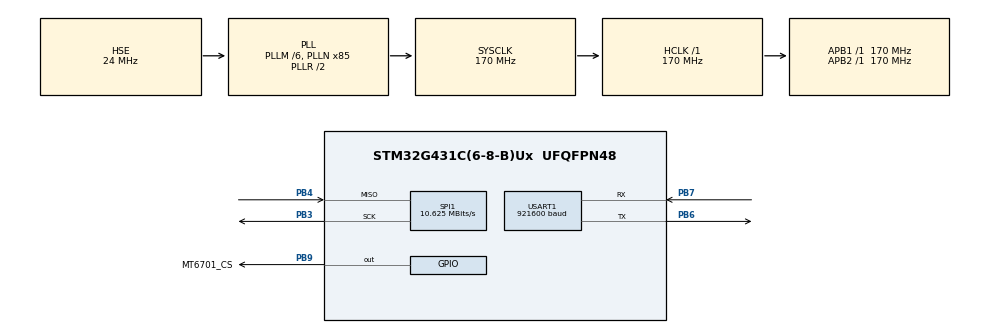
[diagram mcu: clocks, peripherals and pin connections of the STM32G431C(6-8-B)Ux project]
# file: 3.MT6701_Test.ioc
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Dma.Request0=USART1_TX
Dma.USART1_TX.0.Direction=DMA_MEMORY_TO_PERIPH
Dma.USART1_TX.0.EventEnable=DISABLE
Dma.USART1_TX.0.Instance=DMA1_Channel1
Dma.USART1_TX.0.MemDataAlignment=DMA_MDATAALIGN_BYTE
Dma.USART1_TX.0.MemInc=DMA_MINC_ENABLE
Dma.USART1_TX.0.Mode=DMA_NORMAL
Dma.USART1_TX.0.PeriphDataAlignment=DMA_PDATAALIGN_BYTE
Dma.USART1_TX.0.PeriphInc=DMA_PINC_DISABLE
Dma.USART1_TX.0.Polarity=HAL_DMAMUX_REQ_GEN_RISING
Dma.USART1_TX.0.Priority=DMA_PRIORITY_LOW
Dma.USART1_TX.0.RequestNumber=1
Dma.USART1_TX.0.SignalID=NONE
Dma.USART1_TX.0.SyncEnable=DISABLE
Dma.USART1_TX.0.SyncPolarity=HAL_DMAMUX_SYNC_NO_EVENT
Dma.USART1_TX.0.SyncRequestNumber=1
Dma.USART1_TX.0.SyncSignalID=NONE
Mcu.Family=STM32G4
Mcu.Name=STM32G431C(6-8-B)Ux
Mcu.Package=UFQFPN48
NVIC.DMA1_Channel1_IRQn=true\:0\:0\:false\:false\:true\:false\:true\:true
NVIC.PriorityGroup=NVIC_PRIORITYGROUP_4
NVIC.USART1_IRQn=true\:0\:0\:false\:false\:true\:true\:true\:true
PA13.Mode=Serial_Wire
PA13.Signal=SYS_JTMS-SWDIO
PA14.Mode=Serial_Wire
PA14.Signal=SYS_JTCK-SWCLK
PB3.Mode=RX_Only_Simplex_Unidirect_Master
PB3.Signal=SPI1_SCK
PB4.Mode=RX_Only_Simplex_Unidirect_Master
PB4.Signal=SPI1_MISO
PB6.Mode=Asynchronous
PB6.Signal=USART1_TX
PB7.Mode=Asynchronous
PB7.Signal=USART1_RX
PB9.GPIO_Label=MT6701_CS
PB9.GPIO_Speed=GPIO_SPEED_FREQ_MEDIUM
PB9.PinState=GPIO_PIN_SET
PB9.Signal=GPIO_Output
PF0-OSC_IN.Mode=HSE-External-Oscillator
PF0-OSC_IN.Signal=RCC_OSC_IN
PF1-OSC_OUT.Mode=HSE-External-Oscillator
PF1-OSC_OUT.Signal=RCC_OSC_OUT
ProjectManager.HeapSize=0x200
ProjectManager.StackSize=0x400
ProjectManager.TargetToolchain=MDK-ARM V5.32
RCC.ADC12Freq_Value=170000000
RCC.AHBFreq_Value=170000000
RCC.APB1Freq_Value=170000000
RCC.APB1TimFreq_Value=170000000
RCC.APB2Freq_Value=170000000
RCC.APB2TimFreq_Value=170000000
RCC.CortexFreq_Value=170000000
RCC.EXTERNAL_CLOCK_VALUE=12288000
RCC.HCLKFreq_Value=170000000
RCC.HSE_VALUE=24000000
RCC.HSI48_VALUE=48000000
RCC.HSI_VALUE=16000000
RCC.LSE_VALUE=32768
RCC.PLLM=RCC_PLLM_DIV6
RCC.PLLN=85
RCC.PLLSourceVirtual=RCC_PLLSOURCE_HSE
RCC.SYSCLKFreq_VALUE=170000000
RCC.SYSCLKSource=RCC_SYSCLKSOURCE_PLLCLK
RCC.USBFreq_Value=170000000
RCC.VCOOutputFreq_Value=340000000
SPI1.BaudRatePrescaler=SPI_BAUDRATEPRESCALER_16
SPI1.CLKPhase=SPI_PHASE_2EDGE
SPI1.CLKPolarity=SPI_POLARITY_LOW
SPI1.CalculateBaudRate=10.625 MBits/s
SPI1.DataSize=SPI_DATASIZE_16BIT
SPI1.Direction=SPI_DIRECTION_2LINES_RXONLY
SPI1.Mode=SPI_MODE_MASTER
SPI1.VirtualType=VM_MASTER
USART1.BaudRate=921600
USART1.VirtualMode-Asynchronous=VM_ASYNC
VP_SYS_VS_DBSignals.Mode=DisableDeadBatterySignals
board=custom

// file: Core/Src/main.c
/* USER CODE BEGIN Header */
/**
 ******************************************************************************
 * @file           : main.c
 * @brief          : Main program body
 ******************************************************************************
 * @attention
 *
 * Copyright (c) 2024 STMicroelectronics.
 * All rights reserved.
 *
 * This software is licensed under terms that can be found in the LICENSE file
 * in the root directory of this software component.
 * If no LICENSE file comes with this software, it is provided AS-IS.
 *
 ******************************************************************************
 */
/* USER CODE END Header */
#include "main.h"
#include "dma.h"
#include "spi.h"
#include "usart.h"
#include "gpio.h"

/* USER CODE BEGIN Includes */
#include "Serial.h"
#include "MT6701.h"
/* USER CODE END Includes */

void SystemClock_Config(void);

int main(void)
{

  /* MCU Configuration--------------------------------------------------------*/

  /* Reset of all peripherals, Initializes the Flash interface and the Systick. */
  HAL_Init();

  /* Configure the system clock */
  SystemClock_Config();

  /* Initialize all configured peripherals */
  MX_GPIO_Init();
  MX_DMA_Init();
  MX_USART1_UART_Init();
  MX_SPI1_Init();
  /* USER CODE BEGIN 2 */
  log_DMA_TX("MT6701 TEST\r\n");
  /* USER CODE END 2 */

  /* Infinite loop */
  /* USER CODE BEGIN WHILE */
  while (1)
  {
    float angle = MT6701_GetRawAngle();
    log_DMA_TX("angle:%f\r\n", angle);
    /* USER CODE END WHILE */

  }
}

void SystemClock_Config(void)
{
  RCC_OscInitTypeDef RCC_OscInitStruct = {0};
  RCC_ClkInitTypeDef RCC_ClkInitStruct = {0};

  /** Configure the main internal regulator output voltage
   */
  HAL_PWREx_ControlVoltageScaling(PWR_REGULATOR_VOLTAGE_SCALE1_BOOST);

  /** Initializes the RCC Oscillators according to the specified parameters
   * in the RCC_OscInitTypeDef structure.
   */
  RCC_OscInitStruct.OscillatorType = RCC_OSCILLATORTYPE_HSE;
  RCC_OscInitStruct.HSEState = RCC_HSE_ON;
  RCC_OscInitStruct.PLL.PLLState = RCC_PLL_ON;
  RCC_OscInitStruct.PLL.PLLSource = RCC_PLLSOURCE_HSE;
  RCC_OscInitStruct.PLL.PLLM = RCC_PLLM_DIV6;
  RCC_OscInitStruct.PLL.PLLN = 85;
  RCC_OscInitStruct.PLL.PLLP = RCC_PLLP_DIV2;
  RCC_OscInitStruct.PLL.PLLQ = RCC_PLLQ_DIV2;
  RCC_OscInitStruct.PLL.PLLR = RCC_PLLR_DIV2;
  if (HAL_RCC_OscConfig(&RCC_OscInitStruct) != HAL_OK)
  {
    Error_Handler();
  }

  /** Initializes the CPU, AHB and APB buses clocks
   */
  RCC_ClkInitStruct.ClockType = RCC_CLOCKTYPE_HCLK | RCC_CLOCKTYPE_SYSCLK | RCC_CLOCKTYPE_PCLK1 | RCC_CLOCKTYPE_PCLK2;
  RCC_ClkInitStruct.SYSCLKSource = RCC_SYSCLKSOURCE_PLLCLK;
  RCC_ClkInitStruct.AHBCLKDivider = RCC_SYSCLK_DIV1;
  RCC_ClkInitStruct.APB1CLKDivider = RCC_HCLK_DIV1;
  RCC_ClkInitStruct.APB2CLKDivider = RCC_HCLK_DIV1;

  if (HAL_RCC_ClockConfig(&RCC_ClkInitStruct, FLASH_LATENCY_4) != HAL_OK)
  {
    Error_Handler();
  }
}

void Error_Handler(void)
{
  __disable_irq();
  while (1)
  {
  }
}
